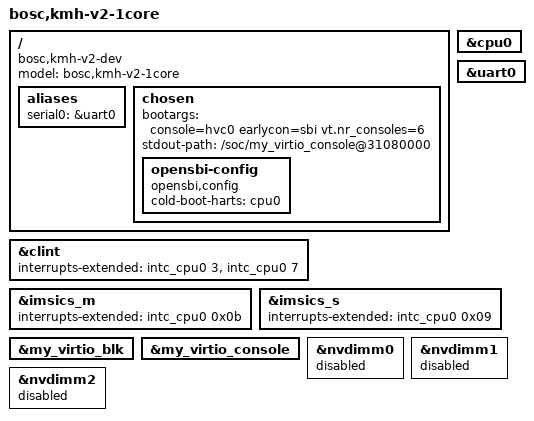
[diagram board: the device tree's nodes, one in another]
// SPDX-License-Identifier: (GPL-2.0 OR MIT)
/* Copyright (c) 2023-2024 BOSC */

/dts-v1/;
#include "kmh-v2.dtsi"

/ {
	#address-cells = <2>;
	#size-cells = <2>;
	compatible = "bosc,kmh-v2-dev";
	model = "bosc,kmh-v2-1core";

	aliases {
		serial0 = &uart0;
	};

	chosen {
		bootargs = "console=hvc0 earlycon=sbi vt.nr_consoles=6";
		stdout-path = "/soc/my_virtio_console@31080000";
		opensbi-config {
		    compatible = "opensbi,config";
		    cold-boot-harts = <&cpu0>;
		};
	};
};

&cpu0 {
	status = "okay";
};

&uart0 {
	status = "okay";
};

&clint {
	interrupts-extended =
		<&intc_cpu0 3>, <&intc_cpu0 7>;
};

&imsics_m {
	interrupts-extended =
		<&intc_cpu0 0x0b>;
};

&imsics_s {
	interrupts-extended =
		<&intc_cpu0 0x09>;
};

&my_virtio_blk {
	status = "okay";
};

&my_virtio_console {
	status = "okay";
};

&nvdimm0 {
	status = "disabled";
};

&nvdimm1 {
	status = "disabled";
};

&nvdimm2 {
	status = "disabled";
};
